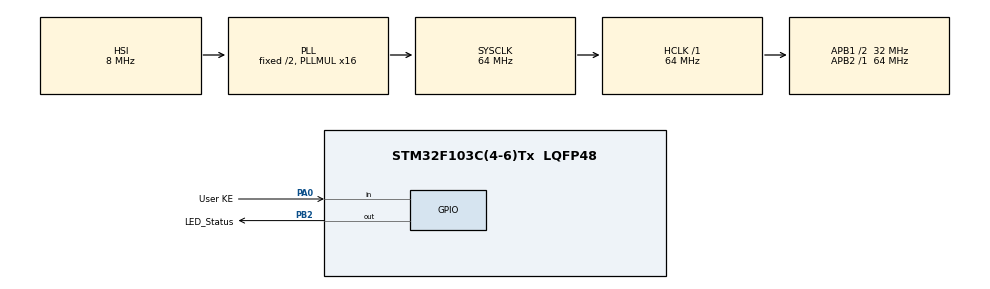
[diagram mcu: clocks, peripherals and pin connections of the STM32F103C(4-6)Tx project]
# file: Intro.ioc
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FREERTOS.BinarySemaphores01=binarySem,Dynamic,NULL,Available
FREERTOS.Tasks01=defaultTask,0,128,DefaultTask,Default,NULL,Dynamic,NULL,NULL;ledOn,0,128,LedOn,Default,NULL,Dynamic,NULL,NULL;ledOff,0,128,LedOff,Default,NULL,Dynamic,NULL,NULL
FREERTOS.configUSE_NEWLIB_REENTRANT=1
Mcu.Family=STM32F1
Mcu.Name=STM32F103C(4-6)Tx
Mcu.Package=LQFP48
NVIC.PriorityGroup=NVIC_PRIORITYGROUP_4
NVIC.TIM3_IRQn=true\:15\:0\:false\:false\:true\:false\:false\:true\:true
NVIC.TimeBase=TIM3_IRQn
NVIC.TimeBaseIP=TIM3
PA0-WKUP.GPIO_Label=User KE
PA0-WKUP.GPIO_Mode=GPIO_MODE_INPUT
PA0-WKUP.GPIO_PuPd=GPIO_NOPULL
PA0-WKUP.Signal=GPIO_Input
PA13.Mode=Serial_Wire
PA13.Signal=SYS_JTMS-SWDIO
PA14.Mode=Serial_Wire
PA14.Signal=SYS_JTCK-SWCLK
PB2.GPIO_Label=LED_Status
PB2.GPIO_Speed=GPIO_SPEED_FREQ_LOW
PB2.Signal=GPIO_Output
ProjectManager.HeapSize=0x200
ProjectManager.StackSize=0x400
ProjectManager.TargetToolchain=STM32CubeIDE
RCC.AHBFreq_Value=64000000
RCC.APB1CLKDivider=RCC_HCLK_DIV2
RCC.APB1Freq_Value=32000000
RCC.APB1TimFreq_Value=64000000
RCC.APB2Freq_Value=64000000
RCC.APB2TimFreq_Value=64000000
RCC.HCLKFreq_Value=64000000
RCC.PLLMUL=RCC_PLL_MUL16
RCC.SYSCLKFreq_VALUE=64000000
RCC.SYSCLKSource=RCC_SYSCLKSOURCE_PLLCLK
RCC.USBFreq_Value=64000000
VP_FREERTOS_VS_CMSIS_V1.Mode=CMSIS_V1
VP_SYS_VS_tim3.Mode=TIM3
board=custom

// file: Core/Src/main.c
/* USER CODE BEGIN Header */
/**
  ******************************************************************************
  * @file           : main.c
  * @brief          : Main program body
  ******************************************************************************
  * @attention
  *
  * Copyright (c) 2024 STMicroelectronics.
  * All rights reserved.
  *
  * This software is licensed under terms that can be found in the LICENSE file
  * in the root directory of this software component.
  * If no LICENSE file comes with this software, it is provided AS-IS.
  *
  ******************************************************************************
  */
/* USER CODE END Header */
#include "main.h"
#include "cmsis_os.h"

/* USER CODE BEGIN Includes */
#include "stdbool.h"
/* USER CODE END Includes */

osThreadId defaultTaskHandle;
osThreadId ledOnHandle;
osThreadId ledOffHandle;
osSemaphoreId binarySemHandle;

void SystemClock_Config(void);
static void MX_GPIO_Init(void);
void DefaultTask(void const * argument);
void LedOn(void const * argument);
void LedOff(void const * argument);

int main(void)
{

  /* MCU Configuration--------------------------------------------------------*/

  /* Reset of all peripherals, Initializes the Flash interface and the Systick. */
  HAL_Init();

  /* Configure the system clock */
  SystemClock_Config();

  /* Initialize all configured peripherals */
  MX_GPIO_Init();

  /* Create the semaphores(s) */
  /* definition and creation of binarySem */
  osSemaphoreDef(binarySem);
  binarySemHandle = osSemaphoreCreate(osSemaphore(binarySem), 1);

  /* Create the thread(s) */
  /* definition and creation of defaultTask */
  osThreadDef(defaultTask, DefaultTask, osPriorityNormal, 0, 128);
  defaultTaskHandle = osThreadCreate(osThread(defaultTask), NULL);

  /* definition and creation of ledOn */
  osThreadDef(ledOn, LedOn, osPriorityNormal, 0, 128);
  ledOnHandle = osThreadCreate(osThread(ledOn), NULL);

  /* definition and creation of ledOff */
  osThreadDef(ledOff, LedOff, osPriorityNormal, 0, 128);
  ledOffHandle = osThreadCreate(osThread(ledOff), NULL);

  /* Start scheduler */
  osKernelStart();

  /* We should never get here as control is now taken by the scheduler */

  /* Infinite loop */
  while (1)
  {

  }
}

void SystemClock_Config(void)
{
  RCC_OscInitTypeDef RCC_OscInitStruct = {0};
  RCC_ClkInitTypeDef RCC_ClkInitStruct = {0};

  /** Initializes the RCC Oscillators according to the specified parameters
  * in the RCC_OscInitTypeDef structure.
  */
  RCC_OscInitStruct.OscillatorType = RCC_OSCILLATORTYPE_HSI;
  RCC_OscInitStruct.HSIState = RCC_HSI_ON;
  RCC_OscInitStruct.HSICalibrationValue = RCC_HSICALIBRATION_DEFAULT;
  RCC_OscInitStruct.PLL.PLLState = RCC_PLL_ON;
  RCC_OscInitStruct.PLL.PLLSource = RCC_PLLSOURCE_HSI_DIV2;
  RCC_OscInitStruct.PLL.PLLMUL = RCC_PLL_MUL16;
  if (HAL_RCC_OscConfig(&RCC_OscInitStruct) != HAL_OK)
  {
    Error_Handler();
  }

  /** Initializes the CPU, AHB and APB buses clocks
  */
  RCC_ClkInitStruct.ClockType = RCC_CLOCKTYPE_HCLK|RCC_CLOCKTYPE_SYSCLK
                              |RCC_CLOCKTYPE_PCLK1|RCC_CLOCKTYPE_PCLK2;
  RCC_ClkInitStruct.SYSCLKSource = RCC_SYSCLKSOURCE_PLLCLK;
  RCC_ClkInitStruct.AHBCLKDivider = RCC_SYSCLK_DIV1;
  RCC_ClkInitStruct.APB1CLKDivider = RCC_HCLK_DIV2;
  RCC_ClkInitStruct.APB2CLKDivider = RCC_HCLK_DIV1;

  if (HAL_RCC_ClockConfig(&RCC_ClkInitStruct, FLASH_LATENCY_2) != HAL_OK)
  {
    Error_Handler();
  }
}

static void MX_GPIO_Init(void)
{
  GPIO_InitTypeDef GPIO_InitStruct = {0};

  /* GPIO Ports Clock Enable */
  __HAL_RCC_GPIOA_CLK_ENABLE();
  __HAL_RCC_GPIOB_CLK_ENABLE();

  /*Configure GPIO pin Output Level */
  HAL_GPIO_WritePin(LED_Status_GPIO_Port, LED_Status_Pin, GPIO_PIN_RESET);

  /*Configure GPIO pin : User_KE_Pin */
  GPIO_InitStruct.Pin = User_KE_Pin;
  GPIO_InitStruct.Mode = GPIO_MODE_INPUT;
  GPIO_InitStruct.Pull = GPIO_NOPULL;
  HAL_GPIO_Init(User_KE_GPIO_Port, &GPIO_InitStruct);

  /*Configure GPIO pin : LED_Status_Pin */
  GPIO_InitStruct.Pin = LED_Status_Pin;
  GPIO_InitStruct.Mode = GPIO_MODE_OUTPUT_PP;
  GPIO_InitStruct.Pull = GPIO_NOPULL;
  GPIO_InitStruct.Speed = GPIO_SPEED_FREQ_LOW;
  HAL_GPIO_Init(LED_Status_GPIO_Port, &GPIO_InitStruct);

}

void DefaultTask(void const * argument)
{
  /* USER CODE BEGIN 5 */
  /* Infinite loop */
  for(;;)
  {

	  osDelay(1000);
  }
  /* USER CODE END 5 */
}

void LedOn(void const * argument)
{
  /* USER CODE BEGIN LedOn */
  /* Infinite loop */
  for(;;)
  {
	  if (osSemaphoreWait(binarySemHandle, osWaitForever) == osOK)
	  {
		  HAL_GPIO_WritePin(GPIOB, GPIO_PIN_2, GPIO_PIN_RESET);
		  osDelay(500);
	  }
  }
  /* USER CODE END LedOn */
}

void LedOff(void const * argument)
{
  /* USER CODE BEGIN LedOff */
  /* Infinite loop */
  for(;;)
  {
	  HAL_GPIO_WritePin(GPIOB, GPIO_PIN_2, GPIO_PIN_SET);
	  osSemaphoreRelease(binarySemHandle);
	  osDelay(500);
  }
  /* USER CODE END LedOff */
}

void HAL_TIM_PeriodElapsedCallback(TIM_HandleTypeDef *htim)
{
  if (htim->Instance == TIM3) {
    HAL_IncTick();
  }
}

void Error_Handler(void)
{
  __disable_irq();
  while (1)
  {
  }
}
